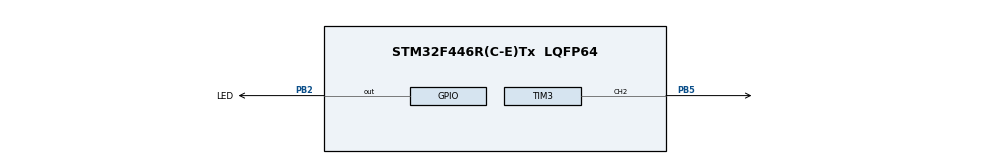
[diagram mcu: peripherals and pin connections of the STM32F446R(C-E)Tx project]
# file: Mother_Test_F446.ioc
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Dma.Request0=TIM3_CH2
Dma.TIM3_CH2.0.Direction=DMA_MEMORY_TO_PERIPH
Dma.TIM3_CH2.0.FIFOMode=DMA_FIFOMODE_DISABLE
Dma.TIM3_CH2.0.Instance=DMA1_Stream5
Dma.TIM3_CH2.0.MemDataAlignment=DMA_MDATAALIGN_WORD
Dma.TIM3_CH2.0.MemInc=DMA_MINC_ENABLE
Dma.TIM3_CH2.0.Mode=DMA_CIRCULAR
Dma.TIM3_CH2.0.PeriphDataAlignment=DMA_PDATAALIGN_WORD
Dma.TIM3_CH2.0.PeriphInc=DMA_PINC_DISABLE
Dma.TIM3_CH2.0.Priority=DMA_PRIORITY_VERY_HIGH
Mcu.Family=STM32F4
Mcu.Name=STM32F446R(C-E)Tx
Mcu.Package=LQFP64
NVIC.DMA1_Stream5_IRQn=true\:0\:0\:false\:false\:true\:false\:true\:true
NVIC.PriorityGroup=NVIC_PRIORITYGROUP_4
PA13.Signal=SYS_JTMS-SWDIO
PA14.Signal=SYS_JTCK-SWCLK
PB2.GPIO_Label=LED
PB2.Signal=GPIO_Output
PB3.Signal=SYS_JTDO-SWO
PB5.GPIO_Speed=GPIO_SPEED_FREQ_HIGH
PB5.Signal=S_TIM3_CH2
ProjectManager.HeapSize=0x200
ProjectManager.StackSize=0x400
ProjectManager.TargetToolchain=STM32CubeIDE
RCC.CortexFreq_Value=16000000
RCC.USBFreq_Value=96000000
RCC.VCOOutputFreq_Value=192000000
SH.S_TIM3_CH2.0=TIM3_CH2,PWM Generation2 CH2
TIM3.Channel-PWM\ Generation2\ CH2=TIM_CHANNEL_2
TIM3.OCFastMode_PWM-PWM\ Generation2\ CH2=TIM_OCFAST_ENABLE
TIM3.Period=20-1
TIM3.Prescaler=1-1
VP_TIM3_VS_ClockSourceINT.Mode=Internal
board=custom

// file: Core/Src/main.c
/* USER CODE BEGIN Header */
/**
  ******************************************************************************
  * @file           : main.c
  * @brief          : Main program body
  ******************************************************************************
  * @attention
  *
  * Copyright (c) 2024 STMicroelectronics.
  * All rights reserved.
  *
  * This software is licensed under terms that can be found in the LICENSE file
  * in the root directory of this software component.
  * If no LICENSE file comes with this software, it is provided AS-IS.
  *
  ******************************************************************************
  */
/* USER CODE END Header */
#include "main.h"

TIM_HandleTypeDef htim3;
DMA_HandleTypeDef hdma_tim3_ch2;

/* USER CODE BEGIN PV */
#define LEDs 20

uint32_t buffer[50+(LEDs*24)];
//				= { // bufferをuint32_t?��?
//		0,0,0,0,0,0,0,0,0,0,
//		0,0,0,0,0,0,0,0,0,0,
//		0,0,0,0,0,0,0,0,0,0,
//		0,0,0,0,0,0,0,0,0,0,
//		0,0,0,0,0,0,0,0,0,0,
//		6,6,6,6,6,6,6,6,
//		6,6,6,6,6,6,6,6,
//		6,6,6,6,6,6,6,6,
//};

/* USER CODE END PV */

void SystemClock_Config(void);
static void MX_GPIO_Init(void);
static void MX_DMA_Init(void);
static void MX_TIM3_Init(void);

int main(void)
{

  /* MCU Configuration--------------------------------------------------------*/

  /* Reset of all peripherals, Initializes the Flash interface and the Systick. */
  HAL_Init();

  /* Configure the system clock */
  SystemClock_Config();

  /* Initialize all configured peripherals */
  MX_GPIO_Init();
  MX_DMA_Init();
  MX_TIM3_Init();
  /* USER CODE BEGIN 2 */
  for(int i=0; i<50+(24*LEDs); i++){
	  if(i<50){
		  buffer[i]=0;
	  }else{
		  buffer[i]=6;
	  }
  }
  HAL_TIM_PWM_Start_DMA(&htim3, TIM_CHANNEL_2, (uint32_t*)buffer, (uint16_t)(50 + (LEDs*24))); // bufferをuint32_tへのキャストしました

  /* USER CODE END 2 */

  /* Infinite loop */
    while (1) {

    }
}

void SystemClock_Config(void)
{
  RCC_OscInitTypeDef RCC_OscInitStruct = {0};
  RCC_ClkInitTypeDef RCC_ClkInitStruct = {0};

  /** Configure the main internal regulator output voltage
  */
  __HAL_RCC_PWR_CLK_ENABLE();
  __HAL_PWR_VOLTAGESCALING_CONFIG(PWR_REGULATOR_VOLTAGE_SCALE3);

  /** Initializes the RCC Oscillators according to the specified parameters
  * in the RCC_OscInitTypeDef structure.
  */
  RCC_OscInitStruct.OscillatorType = RCC_OSCILLATORTYPE_HSI;
  RCC_OscInitStruct.HSIState = RCC_HSI_ON;
  RCC_OscInitStruct.HSICalibrationValue = RCC_HSICALIBRATION_DEFAULT;
  RCC_OscInitStruct.PLL.PLLState = RCC_PLL_NONE;
  if (HAL_RCC_OscConfig(&RCC_OscInitStruct) != HAL_OK)
  {
    Error_Handler();
  }

  /** Initializes the CPU, AHB and APB buses clocks
  */
  RCC_ClkInitStruct.ClockType = RCC_CLOCKTYPE_HCLK|RCC_CLOCKTYPE_SYSCLK
                              |RCC_CLOCKTYPE_PCLK1|RCC_CLOCKTYPE_PCLK2;
  RCC_ClkInitStruct.SYSCLKSource = RCC_SYSCLKSOURCE_HSI;
  RCC_ClkInitStruct.AHBCLKDivider = RCC_SYSCLK_DIV1;
  RCC_ClkInitStruct.APB1CLKDivider = RCC_HCLK_DIV1;
  RCC_ClkInitStruct.APB2CLKDivider = RCC_HCLK_DIV1;

  if (HAL_RCC_ClockConfig(&RCC_ClkInitStruct, FLASH_LATENCY_0) != HAL_OK)
  {
    Error_Handler();
  }
}

static void MX_TIM3_Init(void)
{

  TIM_ClockConfigTypeDef sClockSourceConfig = {0};
  TIM_MasterConfigTypeDef sMasterConfig = {0};
  TIM_OC_InitTypeDef sConfigOC = {0};

  htim3.Instance = TIM3;
  htim3.Init.Prescaler = 1-1;
  htim3.Init.CounterMode = TIM_COUNTERMODE_UP;
  htim3.Init.Period = 20-1;
  htim3.Init.ClockDivision = TIM_CLOCKDIVISION_DIV1;
  htim3.Init.AutoReloadPreload = TIM_AUTORELOAD_PRELOAD_DISABLE;
  if (HAL_TIM_Base_Init(&htim3) != HAL_OK)
  {
    Error_Handler();
  }
  sClockSourceConfig.ClockSource = TIM_CLOCKSOURCE_INTERNAL;
  if (HAL_TIM_ConfigClockSource(&htim3, &sClockSourceConfig) != HAL_OK)
  {
    Error_Handler();
  }
  if (HAL_TIM_PWM_Init(&htim3) != HAL_OK)
  {
    Error_Handler();
  }
  sMasterConfig.MasterOutputTrigger = TIM_TRGO_RESET;
  sMasterConfig.MasterSlaveMode = TIM_MASTERSLAVEMODE_DISABLE;
  if (HAL_TIMEx_MasterConfigSynchronization(&htim3, &sMasterConfig) != HAL_OK)
  {
    Error_Handler();
  }
  sConfigOC.OCMode = TIM_OCMODE_PWM1;
  sConfigOC.Pulse = 0;
  sConfigOC.OCPolarity = TIM_OCPOLARITY_HIGH;
  sConfigOC.OCFastMode = TIM_OCFAST_ENABLE;
  if (HAL_TIM_PWM_ConfigChannel(&htim3, &sConfigOC, TIM_CHANNEL_2) != HAL_OK)
  {
    Error_Handler();
  }
  HAL_TIM_MspPostInit(&htim3);

}

static void MX_DMA_Init(void)
{

  /* DMA controller clock enable */
  __HAL_RCC_DMA1_CLK_ENABLE();

  /* DMA interrupt init */
  /* DMA1_Stream5_IRQn interrupt configuration */
  HAL_NVIC_SetPriority(DMA1_Stream5_IRQn, 0, 0);
  HAL_NVIC_EnableIRQ(DMA1_Stream5_IRQn);

}

static void MX_GPIO_Init(void)
{
  GPIO_InitTypeDef GPIO_InitStruct = {0};

  /* GPIO Ports Clock Enable */
  __HAL_RCC_GPIOB_CLK_ENABLE();
  __HAL_RCC_GPIOA_CLK_ENABLE();

  /*Configure GPIO pin Output Level */
  HAL_GPIO_WritePin(LED_GPIO_Port, LED_Pin, GPIO_PIN_RESET);

  /*Configure GPIO pin : LED_Pin */
  GPIO_InitStruct.Pin = LED_Pin;
  GPIO_InitStruct.Mode = GPIO_MODE_OUTPUT_PP;
  GPIO_InitStruct.Pull = GPIO_NOPULL;
  GPIO_InitStruct.Speed = GPIO_SPEED_FREQ_LOW;
  HAL_GPIO_Init(LED_GPIO_Port, &GPIO_InitStruct);

}

void Error_Handler(void)
{
  __disable_irq();
  while (1)
  {
  }
}
